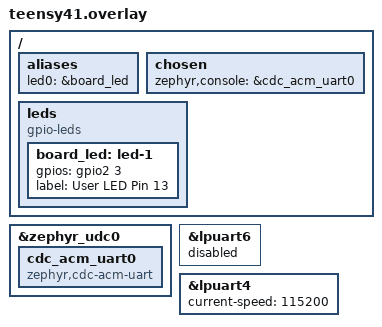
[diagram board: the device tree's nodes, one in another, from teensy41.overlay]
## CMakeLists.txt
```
cmake_minimum_required(VERSION 3.20.0)
set(BOARD teensy41)

find_package(Zephyr)
project(my_zephyr_app)

target_sources(app PRIVATE 
src/main.c
src/matrix/matrix.c
src/network_defs/activation_layer.c
src/network_defs/batchnorm_layer.c
src/network_defs/classifier.c
src/network_defs/connected_layer.c
src/network_defs/convolutional_layer.c
src/network_defs/net.c
src/utils/image.c
src/utils/list.c
src/utils/data.c
)
```

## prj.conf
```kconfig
# Basic Config
CONFIG_GPIO=y
CONFIG_SYS_CLOCK_HW_CYCLES_PER_SEC=600000000
CONFIG_ARM_MPU=y
CONFIG_HW_STACK_PROTECTION=y

# Console, UART and USB related
CONFIG_CONSOLE=y
CONFIG_UART_CONSOLE=y
CONFIG_SERIAL=y
CONFIG_LOG=y
CONFIG_PRINTK=y
# This is from the USB Console example provided by Zephyr
CONFIG_LOG_MODE_IMMEDIATE=y
CONFIG_USB_DEVICE_STACK=y
CONFIG_USB_DEVICE_PID=0x0004
CONFIG_USB_DEVICE_INITIALIZE_AT_BOOT=n
CONFIG_UART_LINE_CTRL=y
CONFIG_CMSIS_DSP=y
CONFIG_NEWLIB_LIBC=y
CONFIG_REQUIRES_FULL_LIBC=y
CONFIG_CMSIS_NN=y
CONFIG_CMSIS_NN_ACTIVATION=y
CONFIG_CMSIS_NN_BASICMATH=y
CONFIG_CMSIS_NN_CONCATENATION=y
CONFIG_CMSIS_NN_CONVOLUTION=y
CONFIG_CMSIS_NN_FULLYCONNECTED=y
CONFIG_CMSIS_NN_NNSUPPORT=y
CONFIG_CMSIS_NN_POOLING=y
CONFIG_CMSIS_NN_RESHAPE=y
CONFIG_CMSIS_NN_SOFTMAX=y
CONFIG_CMSIS_NN_SVD=y
CONFIG_CMSIS_DSP_TRANSFORM=y
CONFIG_UART_LINE_CTRL=y
```

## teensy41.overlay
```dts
/ {

	aliases {
		led0 = &board_led;
	};
	chosen {
      zephyr,console = &cdc_acm_uart0;
    };
  
	leds {
		compatible = "gpio-leds";
		board_led: led-1 {
			gpios = <&gpio2 3 GPIO_ACTIVE_HIGH>;
			label = "User LED Pin 13";
		};
	};
};

&zephyr_udc0 {
	cdc_acm_uart0: cdc_acm_uart0 {
		compatible = "zephyr,cdc-acm-uart";
	};
};

&lpuart6 {
  status = "disabled";
};

&lpuart4 {
  status = "okay";
  current-speed = < 115200 >;
};
```

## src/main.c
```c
#include <stdio.h>
#include <math.h>
#include <stdlib.h>
#include <assert.h>
#include <sys/time.h>
#include <zephyr/kernel.h>

//Zephyr includes for LED & USB
#include <zephyr/drivers/gpio.h>
#include <zephyr/usb/usb_device.h>
#include <zephyr/usb/usbd.h>
#include <zephyr/drivers/uart.h>

//CMSIS-NN for inference
#include <arm_math.h>
#include <arm_nnfunctions.h>

#include "matrix/matrix.h"

#define REPEAT_NUM 3

#define AVGPOOLING_2_OUT_CH		5
#define AVGPOOLING_2_IN_CH		5
#define AVGPOOLING_2_INPUT_W		12
#define AVGPOOLING_2_INPUT_H		1
#define AVGPOOLING_2_DST_SIZE		60
#define AVGPOOLING_2_INPUT_SIZE		60
#define AVGPOOLING_2_OUT_ACTIVATION_MIN -128
#define AVGPOOLING_2_OUT_ACTIVATION_MAX 127
#define AVGPOOLING_2_INPUT_BATCHES	1
#define AVGPOOLING_2_FILTER_X		3
#define AVGPOOLING_2_FILTER_Y		1
#define AVGPOOLING_2_STRIDE_X		1
#define AVGPOOLING_2_STRIDE_Y		2
#define AVGPOOLING_2_PAD_X		1
#define AVGPOOLING_2_PAD_Y		0
#define AVGPOOLING_2_OUTPUT_W		12
#define AVGPOOLING_2_OUTPUT_H		1

const int8_t avgpooling_2_input[60] = {
	-82, -104, 10,	-28, -52, -51, -66, 52,	 124, -74, -21,	 4,  37,   -7,	-33,
	102, 110,  24,	52,  121, 13,  -55, -79, -92, -35, -103, 86, 95,   46,	32,
	-24, -123, 120, 29,  -77, -97, -69, -68, 58,  38,  3,	 3,  79,   -47, 112,
	-52, -113, -46, 107, 68,  83,  -70, 91,	 14,  113, 74,	 73, -103, -98, 25};

const int8_t avgpooling_2_output_ref[60] = {
	-67, -85, 31, 48,  -63, -51, -55, 33,  30, -53, 10,  16,  38,  56,  5,
	31,  20,  -6, -16, 18,	4,   47,  13,  2,  39,	-38, -31, 45,  -6,  -27,
	-75, -35, 49, 44,  -2,	-39, -63, 44,  13, 24,	-49, -60, -12, 39,  73,
	11,  -60, 41, 25,  98,	35,  -37, -19, 8,  69,	79,  2,	  -6,  -42, 69};

// Create USB Device
static const struct device *const dev = DEVICE_DT_GET(DT_CHOSEN(zephyr_console));

int main (void) {
	//Local variables
	uint32_t dtr = 0;

	//If usb enable failed, return
	if (usb_enable(NULL)) {
		return 0;
	}

	//Wait for console to start up
	/* Poll if the DTR flag was set */
	while (!dtr) {
		uart_line_ctrl_get(dev, UART_LINE_CTRL_DTR, &dtr);
		/* Give CPU resources to low priority threads. */
		k_sleep(K_MSEC(100));
	}

	int8_t output[AVGPOOLING_2_DST_SIZE] = {0};

	cmsis_nn_context ctx;
	cmsis_nn_pool_params pool_params;
	cmsis_nn_dims input_dims;
	cmsis_nn_dims filter_dims;
	cmsis_nn_dims output_dims;

	input_dims.n = AVGPOOLING_2_INPUT_BATCHES;
	input_dims.w = AVGPOOLING_2_INPUT_W;
	input_dims.h = AVGPOOLING_2_INPUT_H;
	input_dims.c = AVGPOOLING_2_IN_CH;
	filter_dims.w = AVGPOOLING_2_FILTER_X;
	filter_dims.h = AVGPOOLING_2_FILTER_Y;
	output_dims.w = AVGPOOLING_2_OUTPUT_W;
	output_dims.h = AVGPOOLING_2_OUTPUT_H;
	output_dims.c = AVGPOOLING_2_OUT_CH;

	pool_params.padding.w = AVGPOOLING_2_PAD_X;
	pool_params.padding.h = AVGPOOLING_2_PAD_Y;
	pool_params.stride.w = AVGPOOLING_2_STRIDE_X;
	pool_params.stride.h = AVGPOOLING_2_STRIDE_Y;

	pool_params.activation.min = AVGPOOLING_2_OUT_ACTIVATION_MIN;
	pool_params.activation.max = AVGPOOLING_2_OUT_ACTIVATION_MAX;

	ctx.size = arm_avgpool_s8_get_buffer_size(AVGPOOLING_2_OUTPUT_W, AVGPOOLING_2_IN_CH);
	ctx.buf = malloc(ctx.size);

	arm_cmsis_nn_status result = arm_avgpool_s8(&ctx,
						   &pool_params,
						   &input_dims,
						   avgpooling_2_input,
						   &filter_dims,
						   &output_dims,
						   output);

	free(ctx.buf);

	bool first_run = true;

	while (1)
	{
		if (first_run) {
			for (int i = 0; i < 60; i++){
				printk("Element: %d \n",i);
				printk("Expected: %d, Result %d: \n", avgpooling_2_output_ref[i], output[i]);
				k_msleep(500);
			}
			first_run = false;
		}
	}
	

    return 0;
}
```
